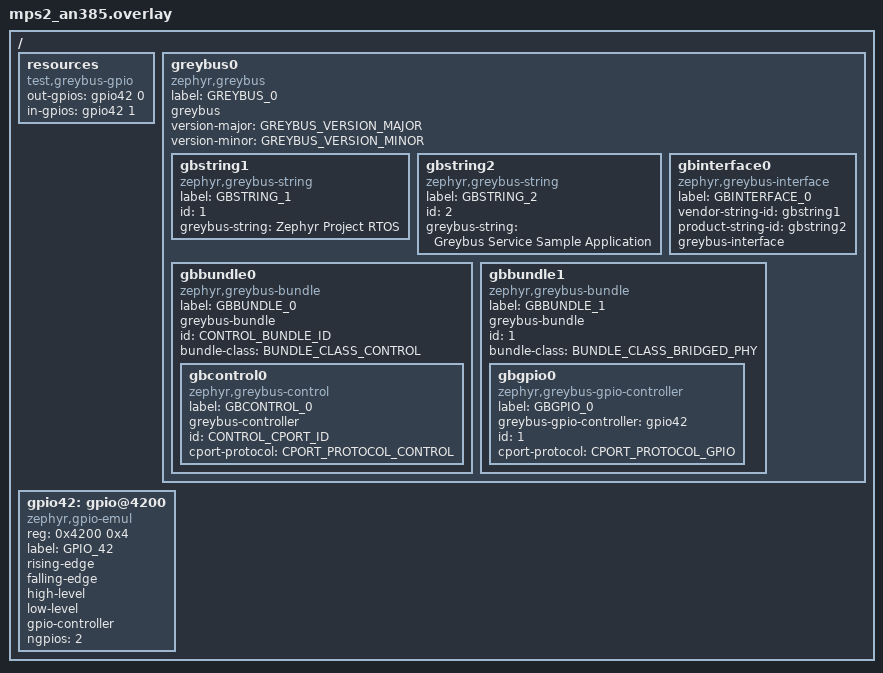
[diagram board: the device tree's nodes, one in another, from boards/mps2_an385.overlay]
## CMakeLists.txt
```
# SPDX-License-Identifier: BSD-3-Clause

#zephyr_include_directories(../../../../include)

cmake_minimum_required(VERSION 3.13.1)
find_package(Zephyr REQUIRED HINTS $ENV{ZEPHYR_BASE})
project(greybus)

if(CONFIG_GREYBUS_ENABLE_TLS)

  set(gen_dir ${ZEPHYR_BINARY_DIR}/include/generated/)

  if(CONFIG_GREYBUS_TLS_CLIENT_VERIFY_OPTIONAL OR CONFIG_GREYBUS_TLS_CLIENT_VERIFY_REQUIRED)

    generate_inc_file_for_target(
      app
      ${ZEPHYR_BASE}/samples/net/sockets/echo_server/src/server.der
      ${gen_dir}/greybus_client.inc
    )

    generate_inc_file_for_target(
      app
      ${ZEPHYR_BASE}/samples/net/sockets/echo_server/src/server_privkey.der
      ${gen_dir}/greybus_client_privkey.inc
    )

  else()

    # if client verification is not needed, then the client needs to
    # load these credentials
    generate_inc_file_for_target(
      app
      ${ZEPHYR_BASE}/samples/net/sockets/echo_server/src/ca.der
      ${gen_dir}/greybus_ca.inc
    )

  endif()
endif()

FILE(GLOB_RECURSE app_sources src/*.c)
target_sources(app PRIVATE ${app_sources})
```

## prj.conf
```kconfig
CONFIG_ZTEST=y

#CONFIG_REQUIRES_FULL_LIBC=y
#CONFIG_NEWLIB_LIBC=y
CONFIG_MINIMAL_LIBC_MALLOC_ARENA_SIZE=16384

CONFIG_GPIO=y
CONFIG_GREYBUS=y
#CONFIG_GB_LOG_LEVEL=4
#CONFIG_GREYBUS_AUDIO=y
#CONFIG_GREYBUS_CAMERA=y
CONFIG_GREYBUS_CONTROL=y
CONFIG_GREYBUS_GPIO=y
#CONFIG_GREYBUS_DEBUG=y
#CONFIG_GREYBUS_HID=y
#CONFIG_GREYBUS_I2C=y
#CONFIG_GREYBUS_LIGHTS=y
#CONFIG_GREYBUS_LOOPBACK=y
#CONFIG_GREYBUS_POWER_SUPPLY=y
#CONFIG_GREYBUS_PWM=y
#CONFIG_GREYBUS_SDIO=y
#CONFIG_GREYBUS_SPI=y
#CONFIG_GREYBUS_UART=y
#CONFIG_GREYBUS_USB=y
#CONFIG_GREYBUS_VIBRATOR=y
CONFIG_CONSOLE_SUBSYS=y
#CONFIG_CONSOLE_GETCHAR=y

# Generic networking options
CONFIG_NETWORKING=y
CONFIG_NET_UDP=y
CONFIG_NET_TCP=y
# We disable IPv6 because most containers / CI environments do
# not enable IPv6 support by default and bind(2), connect(2), etc
# involving IPv6 addresses typically fail.
CONFIG_NET_IPV6=n
CONFIG_NET_IPV4=y
CONFIG_NET_SOCKETS=y
CONFIG_NET_SOCKETS_POSIX_NAMES=y
CONFIG_POSIX_MAX_FDS=32

# Kernel options
CONFIG_MAIN_STACK_SIZE=1024
#CONFIG_ENTROPY_GENERATOR=y
CONFIG_TEST_RANDOM_GENERATOR=y
CONFIG_INIT_STACKS=y

# Logging
CONFIG_NET_LOG=y
CONFIG_LOG=y
CONFIG_NET_STATISTICS=y
CONFIG_PRINTK=y

# Network buffers
CONFIG_NET_PKT_RX_COUNT=4
CONFIG_NET_PKT_TX_COUNT=4
CONFIG_NET_BUF_RX_COUNT=16
CONFIG_NET_BUF_TX_COUNT=16
CONFIG_NET_CONTEXT_NET_PKT_POOL=y

# IP address options
CONFIG_NET_IF_UNICAST_IPV6_ADDR_COUNT=3
CONFIG_NET_IF_MCAST_IPV6_ADDR_COUNT=4
CONFIG_NET_MAX_CONTEXTS=10

# Network shell
CONFIG_NET_SHELL=y
CONFIG_SHELL=y

# Network application options and configuration
CONFIG_NET_CONFIG_SETTINGS=y
CONFIG_NET_CONFIG_MY_IPV6_ADDR="2001:db8::1"
CONFIG_NET_CONFIG_PEER_IPV6_ADDR="2001:db8::2"
CONFIG_NET_CONFIG_MY_IPV4_ADDR="192.0.2.1"
CONFIG_NET_CONFIG_PEER_IPV4_ADDR="192.0.2.2"

# How many client can connect to echo-server simultaneously
#CONFIG_NET_SAMPLE_NUM_HANDLERS=1
```

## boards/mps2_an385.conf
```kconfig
# Copyright (c) 2020 Friedt Professional Engineering Services, Inc
# SPDX-License-Identifier: BSD-3-Clause

# the qemu gpio driver does not seemt to handle tests properly
CONFIG_GPIO_EMUL=y

# for a loopback connection, ipv4 is fine
CONFIG_NET_IPV6=n
CONFIG_NET_CONFIG_NEED_IPV6=n

# Networking Options
CONFIG_NET_LOOPBACK=y
CONFIG_NET_L2_DUMMY=y
CONFIG_TEST_RANDOM_GENERATOR=y
```

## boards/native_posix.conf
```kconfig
# Copyright (c) 2020 Friedt Professional Engineering Services, Inc
# SPDX-License-Identifier: BSD-3-Clause

CONFIG_GPIO_EMUL=y
```

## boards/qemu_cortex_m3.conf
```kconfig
# Copyright (c) 2020 Friedt Professional Engineering Services, Inc
# SPDX-License-Identifier: BSD-3-Clause

# the qemu gpio driver does not seemt to handle tests properly
CONFIG_GPIO_EMUL=y

# for a loopback connection, ipv4 is fine
CONFIG_NET_IPV6=n
CONFIG_NET_CONFIG_NEED_IPV6=n

# Networking Options
CONFIG_NET_LOOPBACK=y
CONFIG_NET_L2_DUMMY=y
CONFIG_TEST_RANDOM_GENERATOR=y
CONFIG_NET_CONFIG_MY_IPV4_ADDR="127.0.0.1"
CONFIG_NET_CONFIG_MY_IPV6_ADDR="::1"
```

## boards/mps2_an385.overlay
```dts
/*
 * Copyright (c) 2020 Friedt Professional Engineering Services, Inc
 *
 * SPDX-License-Identifier: Apache-2.0
 */
 #include <dt-bindings/greybus/greybus.h>

/ {
	resources {
		compatible = "test,greybus-gpio";
		out-gpios = <&gpio42 0 0>;
		in-gpios = <&gpio42 1 0>;
	};

	greybus0: greybus0 {
		compatible = "zephyr,greybus";
		label = "GREYBUS_0";
		greybus;
	};
	
    gpio42: gpio@4200 {
        status = "okay";
        compatible = "zephyr,gpio-emul";
        reg = <0x4200 0x4>;
        label = "GPIO_42";
        rising-edge;
        falling-edge;
        high-level;
        low-level;
        gpio-controller;
        #gpio-cells = <2>;
    };
};

&gpio42 {
	status = "okay";
	ngpios = <2>;
};

&greybus0 {
	label = "GREYBUS_0";
	status = "okay";
	/* defaults in effect, so this isn't necessary */
	version-major = <GREYBUS_VERSION_MAJOR>;
	version-minor = <GREYBUS_VERSION_MINOR>;

	gbstring1: gbstring1 {
		label = "GBSTRING_1";
		status = "okay";
		compatible = "zephyr,greybus-string";
		id = <1>;
		greybus-string = "Zephyr Project RTOS";
	};

	gbstring2: gbstring2 {
		label = "GBSTRING_2";
		status = "okay";
		compatible = "zephyr,greybus-string";
		id = <2>;
		greybus-string = "Greybus Service Sample Application";
	};

	gbinterface0 {
		label = "GBINTERFACE_0";
		status = "okay";
		compatible = "zephyr,greybus-interface";
		vendor-string-id = <&gbstring1>;
		product-string-id = <&gbstring2>;
		greybus-interface;
	};

	gbbundle0 {
		label = "GBBUNDLE_0";
		status = "okay";
		compatible = "zephyr,greybus-bundle";
		greybus-bundle;
		/* Control Bundle 0
		 * Note: control bundle 0 and control cport 0 are optional
		 * Since instance numbers automatically begin at 0, the id
		 * is a mandatory field for bundles and cports.
		 */
		id = <CONTROL_BUNDLE_ID>;
		bundle-class = <BUNDLE_CLASS_CONTROL>;

		gbcontrol0 {
			label = "GBCONTROL_0";
			status = "okay";
			compatible = "zephyr,greybus-control";
			greybus-controller;
			/* Control CPort 0
			 * Note: control bundle 0 and control cport 0 are optional
			 * Since instance numbers automatically begin at 0, the id
			 * is a mandatory field for bundles and cports.
			 */
			id = <CONTROL_CPORT_ID>;
			cport-protocol = <CPORT_PROTOCOL_CONTROL>; 
		};
	};
	
	gbbundle1 {
		label = "GBBUNDLE_1";
		status = "okay";
		compatible = "zephyr,greybus-bundle";
		greybus-bundle;
		id = <1>;
		bundle-class = <BUNDLE_CLASS_BRIDGED_PHY>;		
				
		gbgpio0 {
			label = "GBGPIO_0";
			status = "okay";
			compatible = "zephyr,greybus-gpio-controller";
			greybus-gpio-controller = <&gpio42>;
			id = <1>;
			cport-protocol = <CPORT_PROTOCOL_GPIO>;
		};
	};
};
```

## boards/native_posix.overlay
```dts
/*
 * Copyright (c) 2020 Friedt Professional Engineering Services, Inc
 *
 * SPDX-License-Identifier: BSD-3-Clause
 */
 #include <dt-bindings/greybus/greybus.h>

/ {
	resources {
		compatible = "test,greybus-gpio";
		out-gpios = <&gpio0 0 0>; 
		in-gpios = <&gpio0 1 0>;
	};

	greybus0: greybus0 {
		compatible = "zephyr,greybus";
		label = "GREYBUS_0";
		greybus;
	};
};

&gpio0 {
	status = "okay";
	ngpios = <2>;
};

&greybus0 {
	label = "GREYBUS_0";
	status = "okay";
	/* defaults in effect, so this isn't necessary */
	version-major = <GREYBUS_VERSION_MAJOR>;
	version-minor = <GREYBUS_VERSION_MINOR>;

	gbstring1: gbstring1 {
		label = "GBSTRING_1";
		status = "okay";
		compatible = "zephyr,greybus-string";
		id = <1>;
		greybus-string = "Zephyr Project RTOS";
	};

	gbstring2: gbstring2 {
		label = "GBSTRING_2";
		status = "okay";
		compatible = "zephyr,greybus-string";
		id = <2>;
		greybus-string = "Greybus Service Sample Application";
	};

	gbinterface0 {
		label = "GBINTERFACE_0";
		status = "okay";
		compatible = "zephyr,greybus-interface";
		vendor-string-id = <&gbstring1>;
		product-string-id = <&gbstring2>;
		greybus-interface;
	};

	gbbundle0 {
		label = "GBBUNDLE_0";
		status = "okay";
		compatible = "zephyr,greybus-bundle";
		greybus-bundle;
		/* Control Bundle 0
		 * Note: control bundle 0 and control cport 0 are optional
		 * Since instance numbers automatically begin at 0, the id
		 * is a mandatory field for bundles and cports.
		 */
		id = <CONTROL_BUNDLE_ID>;
		bundle-class = <BUNDLE_CLASS_CONTROL>;

		gbcontrol0 {
			label = "GBCONTROL_0";
			status = "okay";
			compatible = "zephyr,greybus-control";
			greybus-controller;
			/* Control CPort 0
			 * Note: control bundle 0 and control cport 0 are optional
			 * Since instance numbers automatically begin at 0, the id
			 * is a mandatory field for bundles and cports.
			 */
			id = <CONTROL_CPORT_ID>;
			cport-protocol = <CPORT_PROTOCOL_CONTROL>; 
		};
	};
	
	gbbundle1 {
		label = "GBBUNDLE_1";
		status = "okay";
		compatible = "zephyr,greybus-bundle";
		greybus-bundle;
		id = <1>;
		bundle-class = <BUNDLE_CLASS_BRIDGED_PHY>;		
				
		gbgpio0 {
			label = "GBGPIO_0";
			status = "okay";
			compatible = "zephyr,greybus-gpio-controller";
			greybus-gpio-controller = <&gpio0>;
			id = <1>;
			cport-protocol = <CPORT_PROTOCOL_GPIO>;
		};
	};
};
```

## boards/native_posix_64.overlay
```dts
#include "native_posix.overlay"
```

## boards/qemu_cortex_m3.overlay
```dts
/*
 * Copyright (c) 2020 Friedt Professional Engineering Services, Inc
 *
 * SPDX-License-Identifier: BSD-3-Clause
 */
 #include <dt-bindings/greybus/greybus.h>

/ {
	resources {
		compatible = "test,greybus-gpio";
		out-gpios = <&gpio42 0 0>;
		in-gpios = <&gpio42 1 0>;
	};

	greybus0: greybus0 {
		compatible = "zephyr,greybus";
		label = "GREYBUS_0";
		greybus;
	};
	
    gpio42: gpio@4200 {
        status = "okay";
        compatible = "zephyr,gpio-emul";
        reg = <0x4200 0x4>;
        label = "GPIO_42";
        rising-edge;
        falling-edge;
        high-level;
        low-level;
        gpio-controller;
        #gpio-cells = <2>;
    };
};

&gpio42 {
	status = "okay";
	ngpios = <2>;
};

&greybus0 {
	label = "GREYBUS_0";
	status = "okay";
	/* defaults in effect, so this isn't necessary */
	version-major = <GREYBUS_VERSION_MAJOR>;
	version-minor = <GREYBUS_VERSION_MINOR>;

	gbstring1: gbstring1 {
		label = "GBSTRING_1";
		status = "okay";
		compatible = "zephyr,greybus-string";
		id = <1>;
		greybus-string = "Zephyr Project RTOS";
	};

	gbstring2: gbstring2 {
		label = "GBSTRING_2";
		status = "okay";
		compatible = "zephyr,greybus-string";
		id = <2>;
		greybus-string = "Greybus Service Sample Application";
	};

	gbinterface0 {
		label = "GBINTERFACE_0";
		status = "okay";
		compatible = "zephyr,greybus-interface";
		vendor-string-id = <&gbstring1>;
		product-string-id = <&gbstring2>;
		greybus-interface;
	};

	gbbundle0 {
		label = "GBBUNDLE_0";
		status = "okay";
		compatible = "zephyr,greybus-bundle";
		greybus-bundle;
		/* Control Bundle 0
		 * Note: control bundle 0 and control cport 0 are optional
		 * Since instance numbers automatically begin at 0, the id
		 * is a mandatory field for bundles and cports.
		 */
		id = <CONTROL_BUNDLE_ID>;
		bundle-class = <BUNDLE_CLASS_CONTROL>;

		gbcontrol0 {
			label = "GBCONTROL_0";
			status = "okay";
			compatible = "zephyr,greybus-control";
			greybus-controller;
			/* Control CPort 0
			 * Note: control bundle 0 and control cport 0 are optional
			 * Since instance numbers automatically begin at 0, the id
			 * is a mandatory field for bundles and cports.
			 */
			id = <CONTROL_CPORT_ID>;
			cport-protocol = <CPORT_PROTOCOL_CONTROL>; 
		};
	};
	
	gbbundle1 {
		label = "GBBUNDLE_1";
		status = "okay";
		compatible = "zephyr,greybus-bundle";
		greybus-bundle;
		id = <1>;
		bundle-class = <BUNDLE_CLASS_BRIDGED_PHY>;		
				
		gbgpio0 {
			label = "GBGPIO_0";
			status = "okay";
			compatible = "zephyr,greybus-gpio-controller";
			greybus-gpio-controller = <&gpio42>;
			id = <1>;
			cport-protocol = <CPORT_PROTOCOL_GPIO>;
		};
	};
};
```

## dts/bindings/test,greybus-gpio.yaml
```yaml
#
# Copyright (c) 2019 Nordic Semiconductor ASA
#
# SPDX-License-Identifier: BSD-3-Clause
#

description: |
    This binding provides resources required to build and run the
    gpio-related tests under tests/subsys/greybus test in Zephyr.

compatible: "test,greybus-gpio"

properties:
    out-gpios:
        type: phandle-array
        required: true
        description: |
          Identity of a GPIO that will be configured as an output.  This
          must be on the same device as in-gpios, and physically
          connected to in-gpios.

    in-gpios:
        type: phandle-array
        required: true
        description: |
          Identity of a GPIO that will be configured as an input.  This
          must be on the same device as out-gpios,and physically
          connected to out-gpios.
```

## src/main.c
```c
/*
 * Copyright (c) 2020 Friedt Professional Engineering Services, Inc
 *
 * SPDX-License-Identifier: BSD-3-Clause
 */

#include <ztest.h>

extern void test_greybus_gpio_protocol_version(void);
extern void test_greybus_gpio_cport_shutdown(void);
extern void test_greybus_gpio_line_count(void);
extern void test_greybus_gpio_activate(void);
extern void test_greybus_gpio_deactivate(void);
extern void test_greybus_gpio_get_direction(void);
extern void test_greybus_gpio_direction_input(void);
extern void test_greybus_gpio_direction_output(void);
extern void test_greybus_gpio_get_value(void);
extern void test_greybus_gpio_set_value(void);
extern void test_greybus_gpio_set_debounce(void);
extern void test_greybus_gpio_irq_type(void);
extern void test_greybus_gpio_irq_mask(void);
extern void test_greybus_gpio_irq_unmask(void);
extern void test_greybus_gpio_irq_event(void);

static void board_setup(void)
{
	if (IS_ENABLED(CONFIG_GPIO_EMUL)) {
		extern void gpio_emul_setup(void);
		gpio_emul_setup();
	}
}

extern void test_greybus_setup(void);
extern void test_greybus_teardown(void);

void test_main(void) {

	board_setup();
	test_greybus_setup();
    ztest_test_suite(greybus_gpio,
        ztest_unit_test(test_greybus_gpio_protocol_version),
        ztest_unit_test(test_greybus_gpio_cport_shutdown),
        ztest_unit_test(test_greybus_gpio_line_count),
        ztest_unit_test(test_greybus_gpio_activate),
        ztest_unit_test(test_greybus_gpio_deactivate),
        ztest_unit_test(test_greybus_gpio_get_direction),
        ztest_unit_test(test_greybus_gpio_direction_input),
        ztest_unit_test(test_greybus_gpio_direction_output),
        ztest_unit_test(test_greybus_gpio_get_value),
        ztest_unit_test(test_greybus_gpio_set_value),
        ztest_unit_test(test_greybus_gpio_set_debounce),
        ztest_unit_test(test_greybus_gpio_irq_type),
        ztest_unit_test(test_greybus_gpio_irq_mask),
        ztest_unit_test(test_greybus_gpio_irq_unmask),
        ztest_unit_test(test_greybus_gpio_irq_event)
        );
    ztest_run_test_suite(greybus_gpio);
    test_greybus_teardown();
}
```

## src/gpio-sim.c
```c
/*
 * Copyright (c) 2020 Friedt Professional Engineering Services, Inc
 *
 * SPDX-License-Identifier: BSD-3-Clause
 */

#include <drivers/gpio/gpio_emul.h>
#include <sys/util.h>
#include <zephyr.h>

#include "test-greybus-gpio.h"

/*
 * When GPIO are simulated, this callback can be used to implement the
 * "wiring". E.g. in this test application, PIN_OUT is connected to
 * PIN_IN. When PIN_OUT is set high or low, PIN_IN must be set
 * correspondingly, as if a wire were connecting the two.
 */

static void gpio_emul_callback_handler(struct device *port,
				      struct gpio_callback *cb,
				      gpio_port_pins_t pins)
{
	int r;
	int val;
	uint32_t output_flags;
	uint32_t input_flags;

	__ASSERT(pins & cb->pin_mask, "invalid mask: %x", pins);

	r = gpio_emul_flags_get(port, GPIO_PIN_OUT, &output_flags);
	__ASSERT(r == 0, "gpio_emul_flags_get() failed: %d", r);
	r = gpio_emul_flags_get(port, GPIO_PIN_IN, &input_flags);
	__ASSERT(r == 0, "gpio_emul_flags_get() failed: %d", r);

	if ((output_flags & GPIO_OUTPUT) && (input_flags & GPIO_INPUT)) {
		r = gpio_emul_output_get(port, GPIO_PIN_OUT);
		__ASSERT(r == 0 || r == 1, "gpio_emul_output_get() failed: %d", r);
		val = r;
		r = gpio_emul_input_set(port, GPIO_PIN_IN, val);
		__ASSERT(r == 0, "gpio_emul_input_set() failed: %d", r);

		return;
	}

	if ((output_flags == GPIO_DISCONNECTED) && (input_flags & GPIO_INPUT)) {
		if (input_flags & GPIO_PULL_UP) {
			val = 1;
		} else {
			/* either GPIO_PULL_DOWN or no input */
			val = 0;
		}

		r = gpio_emul_input_set(port, GPIO_PIN_IN, val);
		__ASSERT(r == 0, "gpio_emul_input_set() failed: %d", r);

		return;
	}
}

static struct gpio_callback gpio_emul_callback = {
	.handler = gpio_emul_callback_handler,
	.pin_mask = BIT(GPIO_PIN_IN) | BIT(GPIO_PIN_OUT),
};

void gpio_emul_setup(void)
{
	struct device *dev = device_get_binding(GPIO_DEV_NAME);
	__ASSERT(dev != NULL, "Device not found");
	int rc = gpio_add_callback(dev, &gpio_emul_callback);
	__ASSERT(rc == 0, "gpio_add_callback() failed: %d", rc);
}
```

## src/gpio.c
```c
/*
 * Copyright (c) 2020 Friedt Professional Engineering Services, Inc
 *
 * SPDX-License-Identifier: BSD-3-Clause
 */

#include <device.h>
#include <errno.h>
#include <greybus/greybus.h>
#include <string.h>
#include <sys/util.h>
#include <ztest.h>
#include <zephyr.h>

#if defined(CONFIG_BOARD_NATIVE_POSIX_64BIT) \
    || defined(CONFIG_BOARD_NATIVE_POSIX_32BIT) \
    || defined(CONFIG_BOARD_NRF52_BSIM)

#include <arpa/inet.h>
#include <netinet/in.h>
#include <poll.h>
#include <sys/byteorder.h>
#include <sys/types.h>
#include <sys/socket.h>
#include <unistd.h>

/* For some reason, including <net/net_ip.h> breaks everything
 * I only need these */
static inline struct sockaddr_in *net_sin(struct sockaddr *sa)
{
	return (struct sockaddr_in *)sa;
}

static inline struct sockaddr_in6 *net_sin6(struct sockaddr *sa)
{
	return (struct sockaddr_in6 *)sa;
}

#else

#include <net/net_ip.h>
#include <net/socket.h>
#include <posix/unistd.h>

#undef perror
#define perror(s) LOG_ERR("%s", s)

#endif

#include <logging/log.h>
LOG_MODULE_REGISTER(greybus_test_gpio, CONFIG_GREYBUS_LOG_LEVEL);

/* slightly annoying */
#include "../../../../../subsys/greybus/gpio-gb.h"

#include "test-greybus-gpio.h"

#define TIMEOUT_MS 1000
#define PORT 4243

#ifdef CONFIG_NET_CONFIG_MY_IPV4_ADDR
#define MY_IPV4_ADDR CONFIG_NET_CONFIG_MY_IPV4_ADDR
#else
#define MY_IPV4_ADDR ""
#endif

#ifdef CONFIG_NET_CONFIG_MY_IPV6_ADDR
#define MY_IPV6_ADDR CONFIG_NET_CONFIG_MY_IPV6_ADDR
#else
#define MY_IPV6_ADDR ""
#endif

static struct device *gpio_dev;

static int fd = -1;

void test_greybus_setup(void) {

    struct sockaddr sa;
    socklen_t sa_len;
    int family;
    uint16_t *port;
    int r;

	if (IS_ENABLED(CONFIG_NET_IPV6)) {
		family = AF_INET6;
		net_sin6(&sa)->sin6_family = AF_INET6;
		inet_pton(family, MY_IPV6_ADDR, &net_sin6(&sa)->sin6_addr);
		port = &net_sin6(&sa)->sin6_port;
		sa_len = sizeof(struct sockaddr_in6);
	} else if (IS_ENABLED(CONFIG_NET_IPV4)) {
		family = AF_INET;
		net_sin(&sa)->sin_family = AF_INET;
		inet_pton(family, MY_IPV4_ADDR, &net_sin(&sa)->sin_addr);
		port = &net_sin(&sa)->sin_port;
		sa_len = sizeof(struct sockaddr_in);
	} else {
		__ASSERT(false, "Neither IPv6 nor IPv4 is available");
	}

	*port = htons(PORT);

	gpio_dev = (struct device *)device_get_binding(GPIO_DEV_NAME);
	zassert_not_equal(gpio_dev, NULL, "failed to get device binding for " GPIO_DEV_NAME);

    r = socket(family, SOCK_STREAM, 0);
    __ASSERT(r >= 0, "connect: %d", errno);
    fd = r;

    r = connect(fd, &sa, sa_len);
    __ASSERT(r == 0, "connect: %d", errno);
}

void test_greybus_teardown(void) {
	if (fd != -1) {
		close(fd);
		fd = -1;
	}
}

static void tx_rx(const struct gb_operation_hdr *req, struct gb_operation_hdr *rsp, size_t rsp_size)
{

    int r;
    int size;
    struct pollfd pollfd;
    const size_t hdr_size = sizeof(struct gb_operation_hdr);
    uint8_t null[1024];

    size = sys_le16_to_cpu(req->size);
    r = send(fd, req, size, 0);
    zassert_not_equal(r, -1, "send: %s", errno);
    zassert_equal(r, size, "write: expected: %d actual: %d", size, r);

    for(;;) {
		memset(&pollfd, 0, sizeof(pollfd));
		pollfd.fd = fd;
		pollfd.events = POLLIN;

		LOG_DBG("calling poll on 1 file");
		r = poll(&pollfd, 1, TIMEOUT_MS);
		LOG_DBG("poll returned %d", r);
		if (r == 0) {
			LOG_DBG("poll returned 0 (timeout?)");
			continue;
		}
		zassert_not_equal(r, -1, "poll: %s", errno);
		//zassert_not_equal(r, 0, "timeout waiting for response");
		zassert_equal(r, 1, "invalid number of pollfds with data: %d", r);

		LOG_DBG("calling recv on fd %d", fd);
		r = recv(fd, rsp, hdr_size, 0);
		LOG_DBG("recv returned %d", r);
		zassert_not_equal(r, -1, "recv: %s", errno);
		zassert_equal(hdr_size, r, "recv: expected: %u actual: %u", (unsigned)hdr_size, r);

		if (rsp->id != req->id || rsp->type != (GB_TYPE_RESPONSE_FLAG | req->type)) {

			r = recv(fd, null, sys_le16_to_cpu(rsp->size) - hdr_size, 0);
			zassert_not_equal(r, -1, "recv: %s", errno);
			zassert_equal(sys_le16_to_cpu(rsp->size) - hdr_size, r,
				"recv: expected: %u actual: %u",
				sys_le16_to_cpu(rsp->size) - hdr_size);
			/*
			 * Note: Currently, the greybus subsystem sends IRQ events
			 * kind of excessively, because there is no way to query
			 * the gpio subsystem for current pin configuration.
			 * Greybus irq events should naturally only be generated
			 * for input pins for example, and more specifically,
			 * input pins that are configured to generate interrupts!
			 * So we are effectively unable to filter events here until
			 * the ability to query gpio pin configuration is added to
			 * the Zephyr GPIO API.
			 *
			 * See https://github.com/zephyrproject-rtos/zephyr/issues/26938
			 */
			continue;
		}
		if (rsp_size - hdr_size > 0) {
			r = recv(fd, (uint8_t *)rsp + hdr_size, rsp_size - hdr_size, 0);
			zassert_not_equal(r, -1, "recv: %s", errno);
			zassert_equal(r, rsp_size - hdr_size, "expected: %u actual: %d", rsp_size - hdr_size, r);
		}

		zassert_equal(rsp->id, req->id, "expected: 0x%04x actual: 0x%04x", sys_le16_to_cpu(req->id), sys_le16_to_cpu(rsp->id));
		zassert_equal(rsp->type, GB_TYPE_RESPONSE_FLAG | req->type, "expected: %u actual: %u", GB_TYPE_RESPONSE_FLAG | req->type, rsp->type);
		break;
    }
}

void test_greybus_gpio_protocol_version(void) {
    const struct gb_operation_hdr req = {
        .size = sys_cpu_to_le16(sizeof(struct gb_operation_hdr)),
        .id = sys_cpu_to_le16(0xabcd),
        .type = GB_GPIO_TYPE_PROTOCOL_VERSION,
    };
    uint8_t rsp_[
        0
        + sizeof(struct gb_operation_hdr)
        + sizeof(struct gb_gpio_proto_version_response)
        ];
    const size_t rsp_size = sizeof(rsp_);
    struct gb_gpio_proto_version_response *const rsp =
        (struct gb_gpio_proto_version_response *)
        (rsp_ + sizeof(struct gb_operation_hdr));

    tx_rx(&req, (struct gb_operation_hdr *)rsp_, rsp_size);

    zassert_equal(((struct gb_operation_hdr *)rsp_)->result, GB_OP_SUCCESS,
        "expected: GB_OP_SUCCESS actual: %u",
        ((struct gb_operation_hdr *)rsp_)->result);

    /* GB_GPIO_VERSION_MAJOR (0) is buried in subsys/greybus/gpio.c */
	zassert_equal(rsp->major, 0, "expected: %u actual: %u",
        0, rsp->major);

    /* GB_GPIO_VERSION_MINOR (1) is buried in subsys/greybus/gpio.c */
	zassert_equal(rsp->minor, 1, "expected: %u actual: %u",
        1, rsp->minor);
}

void test_greybus_gpio_cport_shutdown(void)
{
	/*
	 * looks like the original NuttX implementation was missing any kind
	 * of cport shutdown request
	 */
}

void test_greybus_gpio_line_count(void)
{
    const struct gb_operation_hdr req = {
        .size = sys_cpu_to_le16(sizeof(struct gb_operation_hdr)),
        .id = sys_cpu_to_le16(0xabcd),
        .type = GB_GPIO_TYPE_LINE_COUNT,
    };
    uint8_t rsp_[
        0
        + sizeof(struct gb_operation_hdr)
        + sizeof(struct gb_gpio_line_count_response)
        ];
    const size_t rsp_size = sizeof(rsp_);
    struct gb_gpio_line_count_response *const rsp =
        (struct gb_gpio_line_count_response *)
        (rsp_ + sizeof(struct gb_operation_hdr));
    size_t expected_count;
    size_t actual_count;

    tx_rx(&req, (struct gb_operation_hdr *)rsp_, rsp_size);

    zassert_equal(((struct gb_operation_hdr *)rsp_)->result, GB_OP_SUCCESS,
        "expected: GB_OP_SUCCESS actual: %u",
        ((struct gb_operation_hdr *)rsp_)->result);

    zassert_not_equal(gpio_dev->config, NULL, "gpio_dev->config invalid");

    expected_count =
        popcount(((const struct gpio_driver_config *)gpio_dev->config)->port_pin_mask);
    actual_count = rsp->count + 1;

    zassert_equal(expected_count, actual_count, "expected: %u actual: %u",
        expected_count, actual_count);
}

void test_greybus_gpio_activate(void)
{
	uint8_t req_[
		 0
		 + sizeof(struct gb_operation_hdr)
		 + sizeof(struct gb_gpio_activate_request)
		 ] = {};
    struct gb_operation_hdr *const req = (struct gb_operation_hdr *)req_;
    struct gb_gpio_activate_request *const activate =
		(struct gb_gpio_activate_request *)
		(req_ + sizeof(struct gb_operation_hdr));

    req->size = sys_cpu_to_le16(sizeof(req_));
    req->id = sys_cpu_to_le16(0xabcd);
    req->type = GB_GPIO_TYPE_ACTIVATE;
    activate->which = GPIO_PIN_IN;

    uint8_t rsp_[
		 0
		 + sizeof(struct gb_operation_hdr)
		 ];
    size_t rsp_size = sizeof(rsp_);

    tx_rx(req, (struct gb_operation_hdr *)rsp_, rsp_size);

    zassert_equal(((struct gb_operation_hdr *)rsp_)->result, GB_OP_SUCCESS,
        "expected: GB_OP_SUCCESS actual: %u",
        ((struct gb_operation_hdr *)rsp_)->result);
}

void test_greybus_gpio_deactivate(void)
{
	uint8_t req_[
		 0
		 + sizeof(struct gb_operation_hdr)
		 + sizeof(struct gb_gpio_activate_request)
		 ] = {};
    struct gb_operation_hdr *const req = (struct gb_operation_hdr *)req_;
    struct gb_gpio_activate_request *const activate =
		(struct gb_gpio_activate_request *)
		(req_ + sizeof(struct gb_operation_hdr));

    req->size = sys_cpu_to_le16(sizeof(req_));
    req->id = sys_cpu_to_le16(0xabcd);
    req->type = GB_GPIO_TYPE_DEACTIVATE;
    activate->which = GPIO_PIN_IN;

    uint8_t rsp_[
		 0
		 + sizeof(struct gb_operation_hdr)
		 ];
    size_t rsp_size = sizeof(rsp_);

    tx_rx(req, (struct gb_operation_hdr *)rsp_, rsp_size);

    zassert_equal(((struct gb_operation_hdr *)rsp_)->result, GB_OP_SUCCESS,
        "expected: GB_OP_SUCCESS actual: %u",
        ((struct gb_operation_hdr *)rsp_)->result);
}

void test_greybus_gpio_get_direction(void)
{
	uint8_t req_[
		 0
		 + sizeof(struct gb_operation_hdr)
		 + sizeof(struct gb_gpio_get_direction_request)
		 ] = {};
    struct gb_operation_hdr *const req = (struct gb_operation_hdr *)req_;
    struct gb_gpio_get_direction_request *const dir_req =
		(struct gb_gpio_get_direction_request *)
		(req_ + sizeof(struct gb_operation_hdr));

    req->size = sys_cpu_to_le16(sizeof(req_));
    req->id = sys_cpu_to_le16(0xabcd);
    req->type = GB_GPIO_TYPE_GET_DIRECTION;
    dir_req->which = GPIO_PIN_IN;

    uint8_t rsp_[
		 0
		 + sizeof(struct gb_operation_hdr)
		 + sizeof(struct gb_gpio_get_direction_response)
		 ];
    size_t rsp_size = sizeof(rsp_);
    struct gb_gpio_get_direction_response *const dir_rsp =
		(struct gb_gpio_get_direction_response *)
		(rsp_ + sizeof(struct gb_operation_hdr));

    tx_rx(req, (struct gb_operation_hdr *)rsp_, rsp_size);

    zassert_equal(((struct gb_operation_hdr *)rsp_)->result, GB_OP_SUCCESS,
        "expected: GB_OP_SUCCESS actual: %u",
        ((struct gb_operation_hdr *)rsp_)->result);

    /* in greybus, 1 means input */
    zassert_equal(1, dir_rsp->direction, "expected: %u actual: %u", 1, dir_rsp->direction);
}

void test_greybus_gpio_direction_input(void)
{
	uint8_t req_[
		 0
		 + sizeof(struct gb_operation_hdr)
		 + sizeof(struct gb_gpio_direction_in_request)
		 ] = {};
    struct gb_operation_hdr *const req = (struct gb_operation_hdr *)req_;
    struct gb_gpio_direction_in_request *const dir_req =
		(struct gb_gpio_direction_in_request *)
		(req_ + sizeof(struct gb_operation_hdr));

    req->size = sys_cpu_to_le16(sizeof(req_));
    req->id = sys_cpu_to_le16(0xabcd);
    req->type = GB_GPIO_TYPE_DIRECTION_IN;
    dir_req->which = GPIO_PIN_IN;

    uint8_t rsp_[
		 0
		 + sizeof(struct gb_operation_hdr)
		 ];
    size_t rsp_size = sizeof(rsp_);

    tx_rx(req, (struct gb_operation_hdr *)rsp_, rsp_size);

    zassert_equal(((struct gb_operation_hdr *)rsp_)->result, GB_OP_SUCCESS,
        "expected: GB_OP_SUCCESS actual: %u",
        ((struct gb_operation_hdr *)rsp_)->result);
}

void test_greybus_gpio_direction_output(void)
{
	int r;

    r = gpio_config(gpio_dev, GPIO_PIN_OUT, GPIO_INPUT);
    zassert_equal(0, r, "gpio_config() failed: %d", r);

    r = gpio_pin_get(gpio_dev, GPIO_PIN_IN);
    zassert_true(r >= 0, "gpio_pin_get() failed: %d", -r);
    zassert_equal(0, r, "expected: %u actual: %u", 0, r);

	uint8_t req_[
		 0
		 + sizeof(struct gb_operation_hdr)
		 + sizeof(struct gb_gpio_direction_out_request)
		 ] = {};
    struct gb_operation_hdr *const req = (struct gb_operation_hdr *)req_;
    struct gb_gpio_direction_out_request *const dir_req =
		(struct gb_gpio_direction_out_request *)
		(req_ + sizeof(struct gb_operation_hdr));

    req->size = sys_cpu_to_le16(sizeof(req_));
    req->id = sys_cpu_to_le16(0xabcd);
    req->type = GB_GPIO_TYPE_DIRECTION_OUT;
    dir_req->which = GPIO_PIN_OUT;
    dir_req->value = 1;

    uint8_t rsp_[
		 0
		 + sizeof(struct gb_operation_hdr)
		 ];
    size_t rsp_size = sizeof(rsp_);

    tx_rx(req, (struct gb_operation_hdr *)rsp_, rsp_size);

    zassert_equal(GB_OP_SUCCESS, ((struct gb_operation_hdr *)rsp_)->result,
        "expected: %u actual: %u", GB_OP_SUCCESS,
        ((struct gb_operation_hdr *)rsp_)->result);

    r = gpio_pin_get(gpio_dev, GPIO_PIN_IN);
    zassert_true(r >= 0, "gpio_pin_get() failed: %d", -r);
    zassert_equal(1, r, "expected: %u actual: %u", 1, r);
}

void test_greybus_gpio_get_value(void)
{
	int r;
	uint8_t req_[
		 0
		 + sizeof(struct gb_operation_hdr)
		 + sizeof(struct gb_gpio_get_value_request)
		 ] = {};
    struct gb_operation_hdr *const req = (struct gb_operation_hdr *)req_;
    struct gb_gpio_get_value_request *const get_req =
		(struct gb_gpio_get_value_request *)
		(req_ + sizeof(struct gb_operation_hdr));

    req->size = sys_cpu_to_le16(sizeof(req_));
    req->id = sys_cpu_to_le16(0xabcd);
    req->type = GB_GPIO_TYPE_GET_VALUE;
    get_req->which = GPIO_PIN_IN;

    /*
     * set PIN_OUT (1), since it is an output and is connected to PIN_IN, which
     * we will subsequently read
     */
    if (gpio_dev == NULL) {
        gpio_dev = (struct device *)device_get_binding(GPIO_DEV_NAME);
        zassert_not_equal(gpio_dev, NULL, "failed to get device binding for " GPIO_DEV_NAME);
    }
    r = gpio_pin_set(gpio_dev, GPIO_PIN_OUT, 1);
    zassert_equal(0, r, "gpio_pin_set() failed: %d", r);

    uint8_t rsp_[
		 0
		 + sizeof(struct gb_operation_hdr)
		 + sizeof(struct gb_gpio_get_value_response)
		 ];
    size_t rsp_size = sizeof(rsp_);
    struct gb_gpio_get_value_response *const get_rsp =
		(struct gb_gpio_get_value_response *)
		(rsp_ + sizeof(struct gb_operation_hdr));

    tx_rx(req, (struct gb_operation_hdr *)rsp_, rsp_size);

    zassert_equal(GB_OP_SUCCESS, ((struct gb_operation_hdr *)rsp_)->result,
        "expected: %u actual: %u", GB_OP_SUCCESS,
        ((struct gb_operation_hdr *)rsp_)->result);

    /*
     * PIN_IN should be set (1), since it is an input and is
     * connected to PIN_OUT
     */
    zassert_equal(1, get_rsp->value, "expected: %u actual: %u", 1, get_rsp->value);
}

void test_greybus_gpio_set_value(void)
{
	int r;
	uint8_t req_[
		 0
		 + sizeof(struct gb_operation_hdr)
		 + sizeof(struct gb_gpio_set_value_request)
		 ] = {};
    struct gb_operation_hdr *const req = (struct gb_operation_hdr *)req_;
    struct gb_gpio_set_value_request *const set_req =
		(struct gb_gpio_set_value_request *)
		(req_ + sizeof(struct gb_operation_hdr));

    req->size = sys_cpu_to_le16(sizeof(req_));
    req->id = sys_cpu_to_le16(0xabcd);
    req->type = GB_GPIO_TYPE_SET_VALUE;
    /* pin 1 is configured as output */
    set_req->which = GPIO_PIN_OUT;
    set_req->value = 1;

    /*
     * set PIN_OUT (1), since it is an output and is connected to PIN_IN, which
     * we will subsequently read
     */
    uint8_t rsp_[
		 0
		 + sizeof(struct gb_operation_hdr)
		 ];
    size_t rsp_size = sizeof(rsp_);

    tx_rx(req, (struct gb_operation_hdr *)rsp_, rsp_size);

    zassert_equal(GB_OP_SUCCESS, ((struct gb_operation_hdr *)rsp_)->result,
        "expected: %u actual: %u", GB_OP_SUCCESS,
        ((struct gb_operation_hdr *)rsp_)->result);

    /*
     * PIN_IN should be set (1), since it is an input and is
     * connected to PIN_OUT
     */
    r = gpio_pin_get(gpio_dev, GPIO_PIN_IN);
    zassert_true(r >= 0, "gpio_pin_get() failed: %d", r);
    zassert_equal(1, r, "expected: 1 actual: %d", 1, r);
}

void test_greybus_gpio_set_debounce(void)
{
	uint8_t req_[
		 0
		 + sizeof(struct gb_operation_hdr)
		 + sizeof(struct gb_gpio_set_debounce_request)
		 ] = {};
    struct gb_operation_hdr *const req = (struct gb_operation_hdr *)req_;
    struct gb_gpio_set_debounce_request *const deb_req =
		(struct gb_gpio_set_debounce_request *)
		(req_ + sizeof(struct gb_operation_hdr));

    req->size = sys_cpu_to_le16(sizeof(req_));
    req->id = sys_cpu_to_le16(0xabcd);
    req->type = GB_GPIO_TYPE_SET_DEBOUNCE;
    deb_req->which = GPIO_PIN_IN;

    uint8_t rsp_[
		 0
		 + sizeof(struct gb_operation_hdr)
		 ];
    size_t rsp_size = sizeof(rsp_);

    uint16_t usecs[] = {
		0, 11,
    };

    for(size_t i = 0; i < ARRAY_SIZE(usecs); ++i) {
		deb_req->usec = usecs[i];

		tx_rx(req, (struct gb_operation_hdr *)rsp_, rsp_size);

		zassert_equal(GB_OP_SUCCESS, ((struct gb_operation_hdr *)rsp_)->result,
			"expected: %u: %u", GB_OP_SUCCESS,
			((struct gb_operation_hdr *)rsp_)->result);
    }
}

void test_greybus_gpio_irq_type(void)
{
	uint8_t req_[
		 0
		 + sizeof(struct gb_operation_hdr)
		 + sizeof(struct gb_gpio_irq_type_request)
		 ] = {};
    struct gb_operation_hdr *const req = (struct gb_operation_hdr *)req_;
    struct gb_gpio_irq_type_request *const irqt_req =
		(struct gb_gpio_irq_type_request *)
		(req_ + sizeof(struct gb_operation_hdr));

    uint8_t irq_types[] = {
		GB_GPIO_IRQ_TYPE_NONE,
		GB_GPIO_IRQ_TYPE_EDGE_RISING,
		GB_GPIO_IRQ_TYPE_EDGE_FALLING,
		GB_GPIO_IRQ_TYPE_EDGE_BOTH,
		GB_GPIO_IRQ_TYPE_LEVEL_HIGH,
		GB_GPIO_IRQ_TYPE_LEVEL_LOW,
    };

    req->size = sys_cpu_to_le16(sizeof(req_));
    req->id = sys_cpu_to_le16(0xabcd);
    req->type = GB_GPIO_TYPE_IRQ_TYPE;
    irqt_req->which = GPIO_PIN_IN;

    uint8_t rsp_[
		 0
		 + sizeof(struct gb_operation_hdr)
		 ];
    size_t rsp_size = sizeof(rsp_);

    for(size_t i = 0; i < ARRAY_SIZE(irq_types); ++i) {
		irqt_req->type = irq_types[i];

		tx_rx(req, (struct gb_operation_hdr *)rsp_, rsp_size);

		zassert_equal(GB_OP_SUCCESS, ((struct gb_operation_hdr *)rsp_)->result,
			"expected: %u actual: %u", GB_OP_SUCCESS,
			((struct gb_operation_hdr *)rsp_)->result);
    }
}

void test_greybus_gpio_irq_mask(void)
{
	uint8_t req_[
		 0
		 + sizeof(struct gb_operation_hdr)
		 + sizeof(struct gb_gpio_irq_mask_request)
		 ] = {};
    struct gb_operation_hdr *const req = (struct gb_operation_hdr *)req_;
    struct gb_gpio_irq_mask_request *const dir_req =
		(struct gb_gpio_irq_mask_request *)
		(req_ + sizeof(struct gb_operation_hdr));

    req->size = sys_cpu_to_le16(sizeof(req_));
    req->id = sys_cpu_to_le16(0xabcd);
    req->type = GB_GPIO_TYPE_IRQ_MASK;
    dir_req->which = GPIO_PIN_IN;

    uint8_t rsp_[
		 0
		 + sizeof(struct gb_operation_hdr)
		 ];
    size_t rsp_size = sizeof(rsp_);

    tx_rx(req, (struct gb_operation_hdr *)rsp_, rsp_size);

    zassert_equal(((struct gb_operation_hdr *)rsp_)->result, GB_OP_SUCCESS,
        "expected: GB_OP_SUCCESS actual: %u",
        ((struct gb_operation_hdr *)rsp_)->result);
}

void test_greybus_gpio_irq_unmask(void)
{
	uint8_t req_[
		 0
		 + sizeof(struct gb_operation_hdr)
		 + sizeof(struct gb_gpio_irq_unmask_request)
		 ] = {};
    struct gb_operation_hdr *const req = (struct gb_operation_hdr *)req_;
    struct gb_gpio_irq_unmask_request *const dir_req =
		(struct gb_gpio_irq_unmask_request *)
		(req_ + sizeof(struct gb_operation_hdr));

    req->size = sys_cpu_to_le16(sizeof(req_));
    req->id = sys_cpu_to_le16(0xabcd);
    req->type = GB_GPIO_TYPE_IRQ_UNMASK;
    dir_req->which = GPIO_PIN_IN;

    uint8_t rsp_[
		 0
		 + sizeof(struct gb_operation_hdr)
		 ];
    size_t rsp_size = sizeof(rsp_);

    tx_rx(req, (struct gb_operation_hdr *)rsp_, rsp_size);

    zassert_equal(((struct gb_operation_hdr *)rsp_)->result, GB_OP_SUCCESS,
        "expected: GB_OP_SUCCESS actual: %u",
        ((struct gb_operation_hdr *)rsp_)->result);
}

void test_greybus_gpio_irq_event(void)
{
    int r;
    struct pollfd pollfd = {};
    uint8_t req_[
		 0
		 + sizeof(struct gb_operation_hdr)
		 + sizeof(struct gb_gpio_irq_event_request)
		 ] = {};
    const size_t req_size = sizeof(req_);
	struct gb_operation_hdr *const req = (struct gb_operation_hdr *)req_;
    struct gb_gpio_irq_event_request *const irq_event_req =
		(struct gb_gpio_irq_event_request *)
		(req_ + sizeof(struct gb_operation_hdr));

    r = gpio_pin_configure(gpio_dev, GPIO_PIN_IN, GPIO_INPUT);
    zassert_equal(0, r, "gpio_pin_interrupt_configure() failed: %d", r);

    r = gpio_pin_interrupt_configure(gpio_dev, GPIO_PIN_IN, GPIO_INT_EDGE_RISING);
    zassert_equal(0, r, "gpio_pin_interrupt_configure() failed: %d", r);

    r = gpio_pin_configure(gpio_dev, GPIO_PIN_OUT, GPIO_OUTPUT);
    zassert_equal(0, r, "gpio_pin_configure() failed: %d", r);

    r = gpio_pin_set(gpio_dev, GPIO_PIN_OUT, 0);
    zassert_equal(0, r, "gpio_pin_set() failed: %d", r);

    r = gpio_pin_set(gpio_dev, GPIO_PIN_OUT, 1);
    zassert_equal(0, r, "gpio_pin_set() failed: %d", r);

    for(;;) {
    	memset(&pollfd, 0, sizeof(pollfd));
		pollfd.fd = fd;
		pollfd.events = POLLIN;

		r = poll(&pollfd, 1, TIMEOUT_MS);
		zassert_not_equal(r, -1, "poll: %d", errno);
		zassert_not_equal(r, 0, "timeout waiting for response");
		zassert_equal(r, 1, "invalid number of pollfds with data: %d", r);

		r = recv(fd, req, req_size, 0);
		zassert_not_equal(r, -1, "read: %d", errno);
		zassert_equal(r, req_size, "expected: %u actual: %d", req_size, r);

		zassert_equal(GB_GPIO_TYPE_IRQ_EVENT, req->type, "expected: %u actual: %u", GB_GPIO_TYPE_IRQ_EVENT, req->type);

		/* Again... cannot query Zephyr GPIO pin configuration, and therefore cannot filter */
		/* zassert_equal(GPIO_PIN_IN, irq_event_req->which, "expected: %u actual: %u", GPIO_PIN_IN, irq_event_req->which); */

		if (GPIO_PIN_IN == irq_event_req->which) {
			break;
		}
    }
}
```

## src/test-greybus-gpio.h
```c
/*
 * Copyright (c) 2020 Friedt Professional Engineering Services, Inc
 *
 * SPDX-License-Identifier: BSD-3-Clause
 */

#ifndef TESTS_SUBSYS_TEST_GREYBUS_GPIO_H_
#define TESTS_SUBSYS_TEST_GREYBUS_GPIO_H_

#ifdef __cplusplus
extern "C" {
#endif

#include <zephyr.h>
#include <drivers/gpio.h>
#include <sys/util.h>
#include <ztest.h>

#ifdef CONFIG_QEMU_TARGET
/* Dirty hack because the Qemu GPIO does not emulate GPIO well enough */
#define GPIO_DEV_NAME "GPIO_42"
#define GPIO_PIN_OUT 0
#define GPIO_PIN_IN 1
#else
#if DT_NODE_HAS_STATUS(DT_INST(0, test_greybus_gpio), okay)
/* Execution of the test requires hardware configuration described in
 * devicetree.  See the test,gpio_basic_api binding local to this test
 * for details.
 *
 * If this is not present devices that have gpio-0, gpio-1, or gpio-2
 * aliases are supported for build-only tests.
 */
#define GPIO_DEV_NAME DT_GPIO_LABEL(DT_INST(0, test_greybus_gpio), out_gpios)
#define GPIO_PIN_OUT DT_GPIO_PIN(DT_INST(0, test_greybus_gpio), out_gpios)
#define GPIO_PIN_IN DT_GPIO_PIN(DT_INST(0, test_greybus_gpio), in_gpios)

#elif DT_NODE_HAS_STATUS(DT_ALIAS(gpio_0), okay)
#define GPIO_DEV_NAME DT_LABEL(DT_ALIAS(gpio_0))
#elif DT_NODE_HAS_STATUS(DT_ALIAS(gpio_1), okay)
#define GPIO_DEV_NAME DT_LABEL(DT_ALIAS(gpio_1))
#elif DT_NODE_HAS_STATUS(DT_ALIAS(gpio_3), okay)
#define GPIO_DEV_NAME DT_LABEL(DT_ALIAS(gpio_3))
#else
#error Unsupported board
#endif

#ifndef GPIO_PIN_OUT
/* For build-only testing use fixed pins. */
#define GPIO_PIN_OUT 2
#define GPIO_PIN_IN 3
#endif
#endif

#ifdef __cplusplus
}
#endif

#endif /* TESTS_SUBSYS_TEST_GREYBUS_GPIO_H_ */
```
